VERSION ""

NS_ :

BS_:

BU_: ECU Dashboard

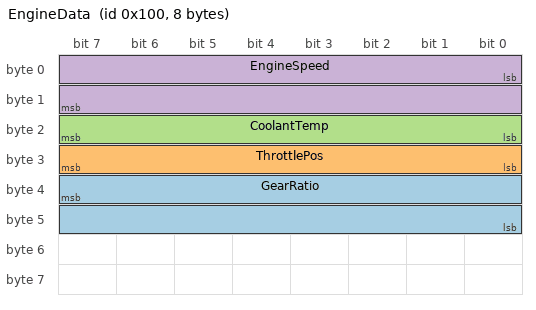
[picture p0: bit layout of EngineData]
BO_ 256 EngineData: 8 ECU
 SG_ GearRatio : 39|16@0+ (0.01,0) [0|655.35] ""  Dashboard
 SG_ ThrottlePos : 24|8@1+ (0.4,0) [0|102] "%"  Dashboard
 SG_ CoolantTemp : 16|8@1+ (1,-40) [-40|215] "degC"  Dashboard
 SG_ EngineSpeed : 0|16@1+ (0.25,0) [0|16383.75] "rpm"  Dashboard

CM_ BO_ 256 "Demo powertrain frame. Mixes Intel and Motorola signals.";
CM_ SG_ 256 GearRatio "Big-endian (Motorola) 16-bit in bytes 4-5; the byte-order gotcha.";
CM_ SG_ 256 ThrottlePos "8-bit, 0.4 percent/bit.";
CM_ SG_ 256 CoolantTemp "8-bit with -40 offset: raw 0 = -40 degC.";
CM_ SG_ 256 EngineSpeed "Little-endian 16-bit, 0.25 rpm/bit. Classic Intel signal.";
